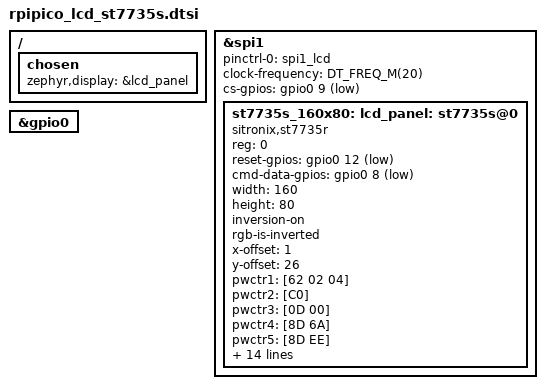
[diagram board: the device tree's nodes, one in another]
/*
 * Copyright (c) 2023 TiaC Systems
 * SPDX-License-Identifier: Apache-2.0
 */

#include <freq.h>
#include <zephyr/dt-bindings/gpio/gpio.h>

/ {
	chosen {
		zephyr,display = &lcd_panel;
	};
};

&spi1 {
	status = "okay";
	pinctrl-0 = <&spi1_lcd>;
	pinctrl-names = "default";

	clock-frequency = <DT_FREQ_M(20)>;
	cs-gpios = <&gpio0 9 GPIO_ACTIVE_LOW>;

	/* LCD with ST7735S controller can use with ST7735R driver. */
	st7735s_160x80: st7735s@0 {
		compatible = "sitronix,st7735r";
		reg = <0>;
		status = "okay";
		reset-gpios = <&gpio0 12 GPIO_ACTIVE_LOW>;
		cmd-data-gpios = <&gpio0 8 GPIO_ACTIVE_LOW>;
		width = <160>;
		height = <80>;
		inversion-on;
		rgb-is-inverted;
		x-offset = <1>;
		y-offset = <26>;
		pwctr1 = [62 02 04];
		pwctr2 = [C0];
		pwctr3 = [0D 00];
		pwctr4 = [8D 6A];
		pwctr5 = [8D EE];
		vmctr1 = <0x0E>;
		frmctr1 = [05 3A 3A];
		frmctr2 = [05 3A 3A];
		frmctr3 = [05 3A 3A 05 3A 3A];
		invctr = <0x03>;
		gamctrp1 = [10 0E 02 03 0E 07 02 07 0A 12 27 37 00 0D 0E 10];
		gamctrn1 = [10 0E 03 03 0F 06 02 08 0A 13 26 36 00 0D 0E 10];
		colmod = <0x05>;
		madctl = <0xA8>; /* rotated: madctl = <0x78>; */
		caset = [00 01 00 A0];
		raset = [00 1A 00 69];

		spi-max-frequency = <DT_FREQ_M(20)>;
	};
};

lcd_panel: &st7735s_160x80 {};

&gpio0 {
	status = "okay";
};
